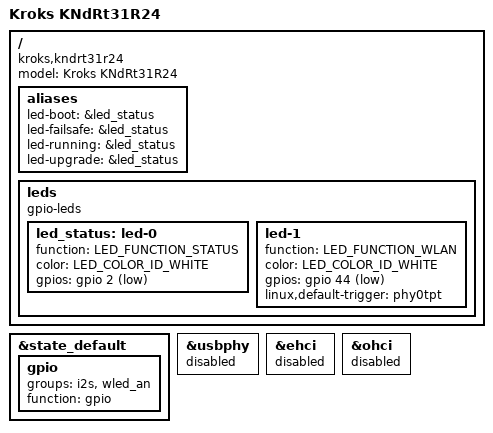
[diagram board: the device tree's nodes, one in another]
#include "mt7628an_kroks_4reth.dtsi"

#include <dt-bindings/leds/common.h>

/ {
	compatible = "kroks,kndrt31r24", "mediatek,mt7628an-soc";
	model = "Kroks KNdRt31R24";

	aliases {
		led-boot = &led_status;
		led-failsafe = &led_status;
		led-running = &led_status;
		led-upgrade = &led_status;
	};

	leds {
		compatible = "gpio-leds";

		led_status: led-0 {
			function = LED_FUNCTION_STATUS;
			color = <LED_COLOR_ID_WHITE>;
			gpios = <&gpio 2 GPIO_ACTIVE_LOW>;
		};

		led-1 {
			function = LED_FUNCTION_WLAN;
			color = <LED_COLOR_ID_WHITE>;
			gpios = <&gpio 44 GPIO_ACTIVE_LOW>;
			linux,default-trigger = "phy0tpt";
		};
	};
};

&state_default {
	gpio {
		groups = "i2s", "wled_an";
		function = "gpio";
	};
};

&usbphy {
	status = "disabled";
};

&ehci {
	status = "disabled";
};

&ohci {
	status = "disabled";
};
